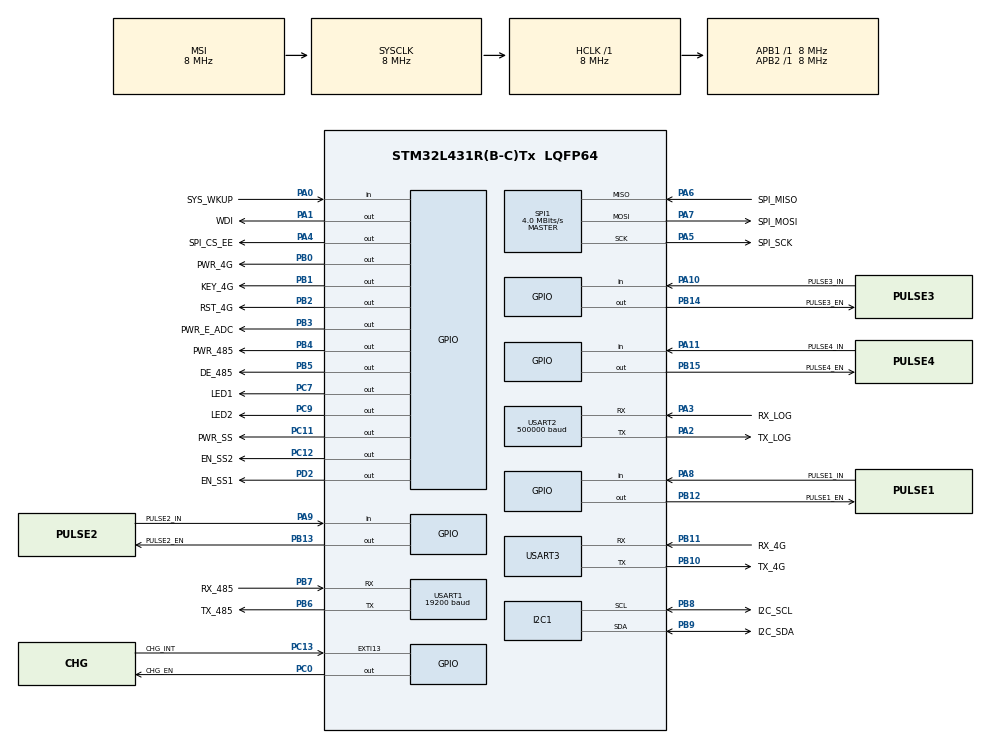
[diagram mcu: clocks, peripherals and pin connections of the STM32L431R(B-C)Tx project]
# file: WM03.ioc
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Dma.Request0=USART1_TX
Dma.Request1=USART1_RX
Dma.Request2=USART2_TX
Dma.Request3=USART2_RX
Dma.Request4=USART3_TX
Dma.Request5=USART3_RX
Dma.USART1_RX.1.Direction=DMA_PERIPH_TO_MEMORY
Dma.USART1_RX.1.Instance=DMA1_Channel5
Dma.USART1_RX.1.MemDataAlignment=DMA_MDATAALIGN_BYTE
Dma.USART1_RX.1.MemInc=DMA_MINC_ENABLE
Dma.USART1_RX.1.Mode=DMA_NORMAL
Dma.USART1_RX.1.PeriphDataAlignment=DMA_PDATAALIGN_BYTE
Dma.USART1_RX.1.PeriphInc=DMA_PINC_DISABLE
Dma.USART1_RX.1.Priority=DMA_PRIORITY_LOW
Dma.USART1_TX.0.Direction=DMA_MEMORY_TO_PERIPH
Dma.USART1_TX.0.Instance=DMA1_Channel4
Dma.USART1_TX.0.MemDataAlignment=DMA_MDATAALIGN_BYTE
Dma.USART1_TX.0.MemInc=DMA_MINC_ENABLE
Dma.USART1_TX.0.Mode=DMA_NORMAL
Dma.USART1_TX.0.PeriphDataAlignment=DMA_PDATAALIGN_BYTE
Dma.USART1_TX.0.PeriphInc=DMA_PINC_DISABLE
Dma.USART1_TX.0.Priority=DMA_PRIORITY_LOW
Dma.USART2_RX.3.Direction=DMA_PERIPH_TO_MEMORY
Dma.USART2_RX.3.Instance=DMA1_Channel6
Dma.USART2_RX.3.MemDataAlignment=DMA_MDATAALIGN_BYTE
Dma.USART2_RX.3.MemInc=DMA_MINC_ENABLE
Dma.USART2_RX.3.Mode=DMA_NORMAL
Dma.USART2_RX.3.PeriphDataAlignment=DMA_PDATAALIGN_BYTE
Dma.USART2_RX.3.PeriphInc=DMA_PINC_DISABLE
Dma.USART2_RX.3.Priority=DMA_PRIORITY_LOW
Dma.USART2_TX.2.Direction=DMA_MEMORY_TO_PERIPH
Dma.USART2_TX.2.Instance=DMA1_Channel7
Dma.USART2_TX.2.MemDataAlignment=DMA_MDATAALIGN_BYTE
Dma.USART2_TX.2.MemInc=DMA_MINC_ENABLE
Dma.USART2_TX.2.Mode=DMA_NORMAL
Dma.USART2_TX.2.PeriphDataAlignment=DMA_PDATAALIGN_BYTE
Dma.USART2_TX.2.PeriphInc=DMA_PINC_DISABLE
Dma.USART2_TX.2.Priority=DMA_PRIORITY_LOW
Dma.USART3_RX.5.Direction=DMA_PERIPH_TO_MEMORY
Dma.USART3_RX.5.Instance=DMA1_Channel3
Dma.USART3_RX.5.MemDataAlignment=DMA_MDATAALIGN_BYTE
Dma.USART3_RX.5.MemInc=DMA_MINC_ENABLE
Dma.USART3_RX.5.Mode=DMA_CIRCULAR
Dma.USART3_RX.5.PeriphDataAlignment=DMA_PDATAALIGN_BYTE
Dma.USART3_RX.5.PeriphInc=DMA_PINC_DISABLE
Dma.USART3_RX.5.Priority=DMA_PRIORITY_LOW
Dma.USART3_TX.4.Direction=DMA_MEMORY_TO_PERIPH
Dma.USART3_TX.4.Instance=DMA1_Channel2
Dma.USART3_TX.4.MemDataAlignment=DMA_MDATAALIGN_BYTE
Dma.USART3_TX.4.MemInc=DMA_MINC_ENABLE
Dma.USART3_TX.4.Mode=DMA_NORMAL
Dma.USART3_TX.4.PeriphDataAlignment=DMA_PDATAALIGN_BYTE
Dma.USART3_TX.4.PeriphInc=DMA_PINC_DISABLE
Dma.USART3_TX.4.Priority=DMA_PRIORITY_LOW
I2C1.Timing=0x00201D2B
IWDG.Prescaler=IWDG_PRESCALER_256
IWDG.Reload=150
Mcu.Family=STM32L4
Mcu.Name=STM32L431R(B-C)Tx
Mcu.Package=LQFP64
NVIC.DMA1_Channel2_IRQn=true\:0\:0\:false\:false\:true\:false\:true\:true
NVIC.DMA1_Channel3_IRQn=true\:0\:0\:false\:false\:true\:false\:true\:true
NVIC.DMA1_Channel4_IRQn=true\:0\:0\:false\:false\:true\:false\:true\:true
NVIC.DMA1_Channel5_IRQn=true\:0\:0\:false\:false\:true\:false\:true\:true
NVIC.DMA1_Channel6_IRQn=true\:0\:0\:false\:false\:true\:false\:true\:true
NVIC.DMA1_Channel7_IRQn=true\:0\:0\:false\:false\:true\:false\:true\:true
NVIC.EXTI15_10_IRQn=true\:0\:0\:false\:false\:true\:true\:true\:true
NVIC.LPTIM1_IRQn=true\:0\:0\:false\:false\:true\:true\:true\:true
NVIC.PriorityGroup=NVIC_PRIORITYGROUP_4
NVIC.RTC_Alarm_IRQn=true\:0\:0\:false\:false\:true\:true\:true\:true
NVIC.RTC_WKUP_IRQn=true\:0\:0\:false\:false\:true\:true\:true\:true
NVIC.USART1_IRQn=true\:0\:0\:false\:false\:true\:true\:true\:true
NVIC.USART2_IRQn=true\:0\:0\:false\:false\:true\:true\:true\:true
NVIC.USART3_IRQn=true\:0\:0\:false\:false\:true\:true\:true\:true
PA0.GPIO_Label=SYS_WKUP
PA0.Signal=GPIO_Input
PA1.GPIO_Label=WDI
PA1.Signal=GPIO_Output
PA10.GPIO_Label=PULSE3_IN
PA10.Signal=GPIO_Input
PA11.GPIO_Label=PULSE4_IN
PA11.Signal=GPIO_Input
PA13\ (JTMS-SWDIO).Mode=Serial_Wire
PA13\ (JTMS-SWDIO).Signal=SYS_JTMS-SWDIO
PA14\ (JTCK-SWCLK).Mode=Serial_Wire
PA14\ (JTCK-SWCLK).Signal=SYS_JTCK-SWCLK
PA2.GPIO_Label=TX_LOG
PA2.Mode=Asynchronous
PA2.Signal=USART2_TX
PA3.GPIO_Label=RX_LOG
PA3.Mode=Asynchronous
PA3.Signal=USART2_RX
PA4.GPIO_Label=SPI_CS_EE
PA4.PinState=GPIO_PIN_SET
PA4.Signal=GPIO_Output
PA5.GPIO_Label=SPI_SCK
PA5.Mode=Full_Duplex_Master
PA5.Signal=SPI1_SCK
PA6.GPIO_Label=SPI_MISO
PA6.Mode=Full_Duplex_Master
PA6.Signal=SPI1_MISO
PA7.GPIO_Label=SPI_MOSI
PA7.Mode=Full_Duplex_Master
PA7.Signal=SPI1_MOSI
PA8.GPIO_Label=PULSE1_IN
PA8.Signal=GPIO_Input
PA9.GPIO_Label=PULSE2_IN
PA9.Signal=GPIO_Input
PB0.GPIO_Label=PWR_4G
PB0.Signal=GPIO_Output
PB1.GPIO_Label=KEY_4G
PB1.Signal=GPIO_Output
PB10.GPIO_Label=TX_4G
PB10.Mode=Asynchronous
PB10.Signal=USART3_TX
PB11.GPIO_Label=RX_4G
PB11.Mode=Asynchronous
PB11.Signal=USART3_RX
PB12.GPIO_Label=PULSE1_EN
PB12.PinState=GPIO_PIN_SET
PB12.Signal=GPIO_Output
PB13.GPIO_Label=PULSE2_EN
PB13.PinState=GPIO_PIN_SET
PB13.Signal=GPIO_Output
PB14.GPIO_Label=PULSE3_EN
PB14.PinState=GPIO_PIN_SET
PB14.Signal=GPIO_Output
PB15.GPIO_Label=PULSE4_EN
PB15.PinState=GPIO_PIN_SET
PB15.Signal=GPIO_Output
PB2.GPIO_Label=RST_4G
PB2.Signal=GPIO_Output
PB3\ (JTDO-TRACESWO).GPIO_Label=PWR_E_ADC
PB3\ (JTDO-TRACESWO).PinState=GPIO_PIN_SET
PB3\ (JTDO-TRACESWO).Signal=GPIO_Output
PB4\ (NJTRST).GPIO_Label=PWR_485
PB4\ (NJTRST).PinState=GPIO_PIN_SET
PB4\ (NJTRST).Signal=GPIO_Output
PB5.GPIO_Label=DE_485
PB5.Signal=GPIO_Output
PB6.GPIO_Label=TX_485
PB6.Mode=Asynchronous
PB6.Signal=USART1_TX
PB7.GPIO_Label=RX_485
PB7.GPIO_PuPd=GPIO_PULLUP
PB7.Mode=Asynchronous
PB7.Signal=USART1_RX
PB8.GPIO_Label=I2C_SCL
PB8.Mode=I2C
PB8.Signal=I2C1_SCL
PB9.GPIO_Label=I2C_SDA
PB9.Mode=I2C
PB9.Signal=I2C1_SDA
PC0.GPIO_Label=CHG_EN
PC0.Signal=GPIO_Output
PC11.GPIO_Label=PWR_SS
PC11.PinState=GPIO_PIN_SET
PC11.Signal=GPIO_Output
PC12.GPIO_Label=EN_SS2
PC12.Signal=GPIO_Output
PC13.GPIO_Label=CHG_INT
PC13.GPIO_ModeDefaultEXTI=GPIO_MODE_IT_FALLING
PC13.Signal=GPXTI13
PC14-OSC32_IN\ (PC14).Mode=LSE-External-Oscillator
PC14-OSC32_IN\ (PC14).Signal=RCC_OSC32_IN
PC15-OSC32_OUT\ (PC15).Mode=LSE-External-Oscillator
PC15-OSC32_OUT\ (PC15).Signal=RCC_OSC32_OUT
PC7.GPIO_Label=LED1
PC7.PinState=GPIO_PIN_SET
PC7.Signal=GPIO_Output
PC9.GPIO_Label=LED2
PC9.PinState=GPIO_PIN_SET
PC9.Signal=GPIO_Output
PD2.GPIO_Label=EN_SS1
PD2.Signal=GPIO_Output
ProjectManager.HeapSize=0x200
ProjectManager.StackSize=0x400
ProjectManager.TargetToolchain=CMake
RCC.ADCFreq_Value=32000000
RCC.AHBFreq_Value=8000000
RCC.APB1Freq_Value=8000000
RCC.APB1TimFreq_Value=8000000
RCC.APB2Freq_Value=8000000
RCC.APB2TimFreq_Value=8000000
RCC.CK48CLockSelection=RCC_USBCLKSOURCE_HSI48
RCC.CortexFreq_Value=8000000
RCC.HCLKFreq_Value=8000000
RCC.HSE_VALUE=8000000
RCC.HSI48_VALUE=48000000
RCC.HSI_VALUE=16000000
RCC.LPTIM1CLockSelection=RCC_LPTIM1CLKSOURCE_LSI
RCC.MSIClockRange=RCC_MSIRANGE_7
RCC.MSI_VALUE=8000000
RCC.RTCClockSelection=RCC_RTCCLKSOURCE_LSE
RCC.SYSCLKFreq_VALUE=8000000
RCC.VCOOutputFreq_Value=64000000
RTC.Alarm-Alarm\ A=RTC_ALARM_A
RTC.AlarmMaskDateWeekDay-Alarm\ A=RTC_ALARMMASK_DATEWEEKDAY
RTC.AlarmMaskHours-Alarm\ A=RTC_ALARMMASK_HOURS
RTC.AlarmMaskMinutes-Alarm\ A=RTC_ALARMMASK_MINUTES
RTC.Format=RTC_FORMAT_BIN
RTC.WakeUpCounter-WakeUp=2047
SPI1.CalculateBaudRate=4.0 MBits/s
SPI1.DataSize=SPI_DATASIZE_8BIT
SPI1.Direction=SPI_DIRECTION_2LINES
SPI1.Mode=SPI_MODE_MASTER
SPI1.VirtualType=VM_MASTER
USART1.BaudRate=19200
USART1.Parity=PARITY_EVEN
USART1.VirtualMode-Asynchronous=VM_ASYNC
USART1.WordLength=WORDLENGTH_9B
USART2.BaudRate=500000
USART2.VirtualMode-Asynchronous=VM_ASYNC
USART3.VirtualMode-Asynchronous=VM_ASYNC
VP_CRC_VS_CRC.Mode=CRC_Activate
VP_IWDG_VS_IWDG.Mode=IWDG_Activate
VP_LPTIM1_VS_LPTIM_counterModeInternalClock.Mode=Counts__internal_clock_event_00
VP_RNG_VS_RNG.Mode=RNG_Activate
VP_RTC_VS_RTC_Activate.Mode=RTC_Enabled
VP_RTC_VS_RTC_Alarm_A_Intern.Mode=Alarm A
VP_RTC_VS_RTC_Calendar.Mode=RTC_Calendar
VP_RTC_VS_RTC_WakeUp_intern.Mode=WakeUp
board=custom

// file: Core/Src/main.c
/* USER CODE BEGIN Header */
/**
  ******************************************************************************
  * @file           : main.c
  * @brief          : Main program body
  ******************************************************************************
  * @attention
  *
  * Copyright (c) 2026 STMicroelectronics.
  * All rights reserved.
  *
  * This software is licensed under terms that can be found in the LICENSE file
  * in the root directory of this software component.
  * If no LICENSE file comes with this software, it is provided AS-IS.
  *
  ******************************************************************************
  */
/* USER CODE END Header */
#include "main.h"
#include "crc.h"
#include "dma.h"
#include "i2c.h"
#include "iwdg.h"
#include "lptim.h"
#include "rng.h"
#include "rtc.h"
#include "spi.h"
#include "usart.h"
#include "gpio.h"

/* USER CODE BEGIN Includes */
#include "boot_main.h"
#include "app_main.h"
/* USER CODE END Includes */

void SystemClock_Config(void);

int main(void)
{

  /* MCU Configuration--------------------------------------------------------*/

  /* Reset of all peripherals, Initializes the Flash interface and the Systick. */
  HAL_Init();

  /* Configure the system clock */
  SystemClock_Config();

  /* USER CODE BEGIN SysInit */
  #ifdef IS_BOOT
  boot_main();
  #elif IS_APP
  /* USER CODE END SysInit */

  /* Initialize all configured peripherals */
  MX_GPIO_Init();
  MX_DMA_Init();
  MX_IWDG_Init();
  MX_USART1_UART_Init();
  MX_USART2_UART_Init();
  MX_USART3_UART_Init();
  MX_SPI1_Init();
  MX_I2C1_Init();
  MX_RTC_Init();
  MX_LPTIM1_Init();
  MX_CRC_Init();
  MX_RNG_Init();
  /* USER CODE BEGIN 2 */
  app_main();
  /* USER CODE END 2 */

  /* Infinite loop */
  while (1)
  {

    /* USER CODE BEGIN 3 */
  }
  #endif
  /* USER CODE END 3 */
}

void SystemClock_Config(void)
{
  RCC_OscInitTypeDef RCC_OscInitStruct = {0};
  RCC_ClkInitTypeDef RCC_ClkInitStruct = {0};

  /** Configure the main internal regulator output voltage
  */
  if (HAL_PWREx_ControlVoltageScaling(PWR_REGULATOR_VOLTAGE_SCALE1) != HAL_OK)
  {
    Error_Handler();
  }

  /** Configure LSE Drive Capability
  */
  HAL_PWR_EnableBkUpAccess();
  __HAL_RCC_LSEDRIVE_CONFIG(RCC_LSEDRIVE_LOW);

  /** Initializes the RCC Oscillators according to the specified parameters
  * in the RCC_OscInitTypeDef structure.
  */
  RCC_OscInitStruct.OscillatorType = RCC_OSCILLATORTYPE_HSI48|RCC_OSCILLATORTYPE_LSI
                              |RCC_OSCILLATORTYPE_LSE|RCC_OSCILLATORTYPE_MSI;
  RCC_OscInitStruct.LSEState = RCC_LSE_ON;
  RCC_OscInitStruct.HSI48State = RCC_HSI48_ON;
  RCC_OscInitStruct.LSIState = RCC_LSI_ON;
  RCC_OscInitStruct.MSIState = RCC_MSI_ON;
  RCC_OscInitStruct.MSICalibrationValue = 0;
  RCC_OscInitStruct.MSIClockRange = RCC_MSIRANGE_7;
  RCC_OscInitStruct.PLL.PLLState = RCC_PLL_NONE;
  if (HAL_RCC_OscConfig(&RCC_OscInitStruct) != HAL_OK)
  {
    Error_Handler();
  }

  /** Initializes the CPU, AHB and APB buses clocks
  */
  RCC_ClkInitStruct.ClockType = RCC_CLOCKTYPE_HCLK|RCC_CLOCKTYPE_SYSCLK
                              |RCC_CLOCKTYPE_PCLK1|RCC_CLOCKTYPE_PCLK2;
  RCC_ClkInitStruct.SYSCLKSource = RCC_SYSCLKSOURCE_MSI;
  RCC_ClkInitStruct.AHBCLKDivider = RCC_SYSCLK_DIV1;
  RCC_ClkInitStruct.APB1CLKDivider = RCC_HCLK_DIV1;
  RCC_ClkInitStruct.APB2CLKDivider = RCC_HCLK_DIV1;

  if (HAL_RCC_ClockConfig(&RCC_ClkInitStruct, FLASH_LATENCY_0) != HAL_OK)
  {
    Error_Handler();
  }

  /** Enable MSI Auto calibration
  */
  HAL_RCCEx_EnableMSIPLLMode();
}

void Error_Handler(void)
{
  __disable_irq();
  while (1)
  {
  }
}
